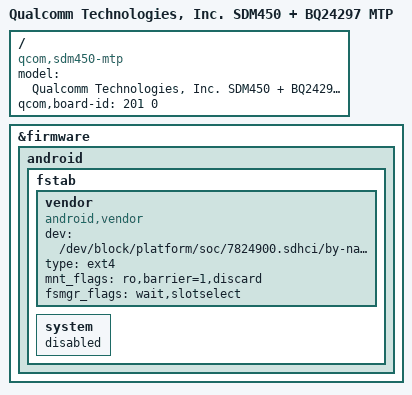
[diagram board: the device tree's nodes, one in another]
/*
 * Copyright (c) 2017, The Linux Foundation. All rights reserved.
 *
 * This program is free software; you can redistribute it and/or modify
 * it under the terms of the GNU General Public License version 2 and
 * only version 2 as published by the Free Software Foundation.
 *
 * This program is distributed in the hope that it will be useful,
 * but WITHOUT ANY WARRANTY; without even the implied warranty of
 * MERCHANTABILITY or FITNESS FOR A PARTICULAR PURPOSE.  See the
 * GNU General Public License for more details.
 */

/dts-v1/;

#include "sdm450.dtsi"
#include "msm-pmi8950.dtsi"
#include "msm8953-mtp.dtsi"
#include "zte-sdm450-blaze.dtsi"

/ {
	model = "Qualcomm Technologies, Inc. SDM450 + BQ24297 MTP";
	compatible = "qcom,sdm450-mtp", "qcom,sdm450", "qcom,mtp";
	qcom,board-id= <201 0>;
};
/*zte add by chenwei10196163 for P840F10 compatible with Android N start. by yuanlin for AB */
&firmware {
	android {
		fstab {
			vendor {
				compatible = "android,vendor";
				dev = "/dev/block/platform/soc/7824900.sdhci/by-name/vendor";
				type = "ext4";
				mnt_flags = "ro,barrier=1,discard";
				fsmgr_flags = "wait,slotselect";
				status = "ok";
			};
			system {
				status = "disabled";
			};
		};
	};
};
/*zte add by chenwei10196163 for P840F10 compatible with Android N end*/

